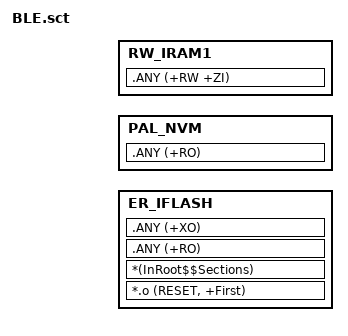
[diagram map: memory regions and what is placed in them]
#! armcc -E -I .\..\

#include "sct_config.h"

; *************************************************************
; *** Scatter-Loading Description File generated by uVision ***
; *************************************************************

; /*-Memory Regions-*/
;#define IROM_start__          0x00000000
;#define IROM_size__           0x00010000
;#define IFLASH_start__        0x10000000
;#define IFLASH_size__         0x00080000
;#define CODE_size__           0x00077FFF
;#define PAL_NVM_DB_START__    0x10078000
;#define PAL_NVM_SIZE          0x00008000
;#define IRAM_start__          0x20000000
;#define IRAM_size__           0x00020000



; /*-Sizes */
;#define size_cstack__  0x6000
;#define size_heap__    0x2000
; /**** End of ICF editor section. ###ICF###*/

#define memory mem with size = 4G;


LR_IFLASH IFLASH_start__  IFLASH_size__  {    ; load region size_region

  ER_IFLASH IFLASH_start__  CODE_size__{   ; load address = execution address
   *.o (RESET, +First)  
   *(InRoot$$Sections)
   .ANY (+RO)
   .ANY (+XO)
  }
  
  PAL_NVM PAL_NVM_DB_START__ PAL_NVM_SIZE { ; RW data
   .ANY (+RO)
  }
 
  RW_IRAM1 IRAM_start__ IRAM_size__  {  ; RW data
   .ANY (+RW +ZI)
  }
  
  
  
}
